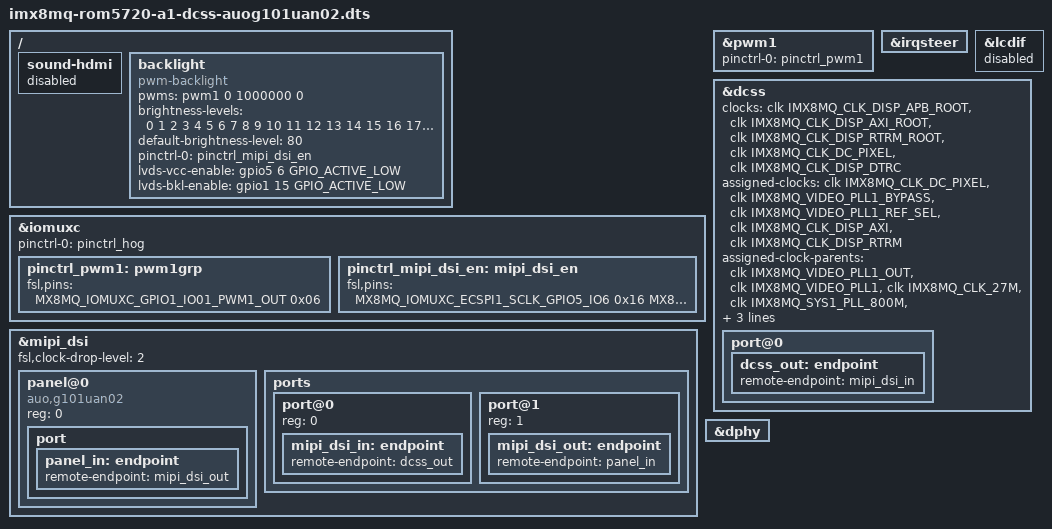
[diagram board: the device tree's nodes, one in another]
// SPDX-License-Identifier: GPL-2.0
/*
 * Copyright 2019 NXP.
 */

#include "imx8mq-rom5720-a1.dts"

/ {
	sound-hdmi {
		status = "disabled";
	};
	backlight: backlight {
		compatible = "pwm-backlight";
		pwms = <&pwm1 0 1000000 0>;
		brightness-levels = < 0  1  2  3  4  5  6  7  8  9
			     10 11 12 13 14 15 16 17 18 19
			     20 21 22 23 24 25 26 27 28 29
			     30 31 32 33 34 35 36 37 38 39
			     40 41 42 43 44 45 46 47 48 49
			     50 51 52 53 54 55 56 57 58 59
			     60 61 62 63 64 65 66 67 68 69
			     70 71 72 73 74 75 76 77 78 79
			     80 81 82 83 84 85 86 87 88 89
			     90 91 92 93 94 95 96 97 98 99
			    100>;
		default-brightness-level = <80>;
	};
};

&iomuxc {
	pinctrl-names = "default";
	pinctrl-0 = <&pinctrl_hog>;
	pinctrl_pwm1: pwm1grp {
		fsl,pins = <
			MX8MQ_IOMUXC_GPIO1_IO01_PWM1_OUT         0x06
		>;
	};
	pinctrl_mipi_dsi_en: mipi_dsi_en {
		fsl,pins = <
			MX8MQ_IOMUXC_ECSPI1_SCLK_GPIO5_IO6	0x16	/* LCD0_VDD_EN */
			MX8MQ_IOMUXC_GPIO1_IO15_GPIO1_IO15	0x16	/* LCD0_BKLT_EN */
		>;
	};
};

&pwm1 {
 	status = "okay";
        pinctrl-names = "default";
        pinctrl-0 = <&pinctrl_pwm1>;

};

/delete-node/&hdmi;

&irqsteer {
	status = "okay";
};

&lcdif {
	status = "disabled";
};

&dcss {
	status = "okay";

	clocks = <&clk IMX8MQ_CLK_DISP_APB_ROOT>,
		 <&clk IMX8MQ_CLK_DISP_AXI_ROOT>,
		 <&clk IMX8MQ_CLK_DISP_RTRM_ROOT>,
		 <&clk IMX8MQ_CLK_DC_PIXEL>,
		 <&clk IMX8MQ_CLK_DISP_DTRC>;
	clock-names = "apb", "axi", "rtrm", "pix", "dtrc";
	assigned-clocks = <&clk IMX8MQ_CLK_DC_PIXEL>,
					  <&clk IMX8MQ_VIDEO_PLL1_BYPASS>,
					  <&clk IMX8MQ_VIDEO_PLL1_REF_SEL>,
					  <&clk IMX8MQ_CLK_DISP_AXI>,
					  <&clk IMX8MQ_CLK_DISP_RTRM>;
	assigned-clock-parents = <&clk IMX8MQ_VIDEO_PLL1_OUT>,
							 <&clk IMX8MQ_VIDEO_PLL1>,
							 <&clk IMX8MQ_CLK_27M>,
							 <&clk IMX8MQ_SYS1_PLL_800M>,
							 <&clk IMX8MQ_SYS1_PLL_800M>;
	assigned-clock-rates = <600000000>, <0>, <0>,
						   <800000000>,
						   <400000000>;

	port@0 {
		dcss_out: endpoint {
			remote-endpoint = <&mipi_dsi_in>;
		};
	};
};

&mipi_dsi {
	status = "okay";
	fsl,clock-drop-level = <2>;

	panel@0 {
		compatible = "auo,g101uan02";
		reg = <0>;
		port {
			panel_in: endpoint {
				remote-endpoint = <&mipi_dsi_out>;
			};
		};
	};

	ports {
		#address-cells = <1>;
		#size-cells = <0>;

		port@0 {
			reg = <0>;
			mipi_dsi_in: endpoint {
				remote-endpoint = <&dcss_out>;
			};
		};

		port@1 {
			reg = <1>;
			mipi_dsi_out: endpoint {
				remote-endpoint = <&panel_in>;
			};
		};
	};
};

&dphy {
	status = "okay";
};


&backlight {
	pinctrl-0 = <&pinctrl_mipi_dsi_en>;
	pinctrl-names = "default";
	lvds-vcc-enable = <&gpio5 6 GPIO_ACTIVE_LOW>;
	lvds-bkl-enable = <&gpio1 15 GPIO_ACTIVE_LOW>;
        status = "okay";
};

